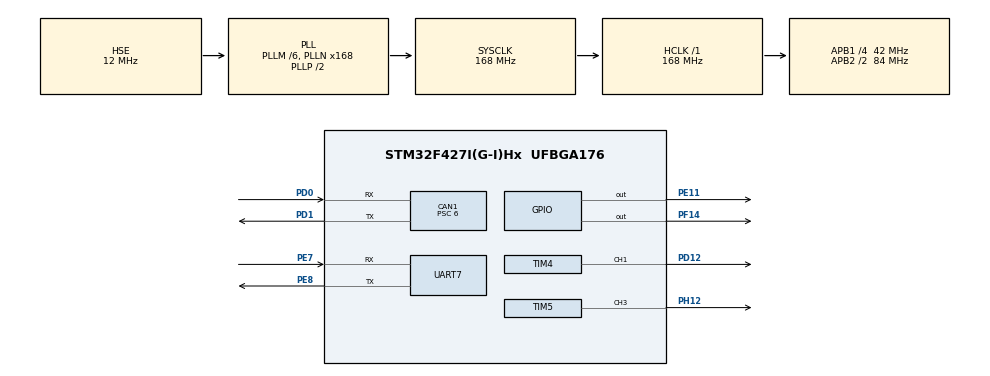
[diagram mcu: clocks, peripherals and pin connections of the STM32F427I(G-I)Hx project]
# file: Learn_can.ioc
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CAN1.AutoBusOff=DISABLE
CAN1.AutoRetransmission=DISABLE
CAN1.AutoWakeUp=DISABLE
CAN1.BS1=CAN_BS1_4TQ
CAN1.BS2=CAN_BS2_2TQ
CAN1.CalculateBaudRate=1000000
CAN1.CalculateTimeBit=1000
CAN1.CalculateTimeQuantum=142.85714285714286
CAN1.Mode=CAN_MODE_NORMAL
CAN1.Prescaler=6
CAN1.ReceiveFifoLocked=DISABLE
CAN1.SyncJumpWidth=CAN_SJW_1TQ
CAN1.TimeSeg1=CAN_BS1_4TQ
CAN1.TimeSeg2=CAN_BS2_2TQ
CAN1.TimeTriggeredMode=DISABLE
CAN1.TransmitFifoPriority=DISABLE
Mcu.Family=STM32F4
Mcu.Name=STM32F427I(G-I)Hx
Mcu.Package=UFBGA176
NVIC.CAN1_RX0_IRQn=true\:0\:0\:false\:false\:true\:true\:true\:true
NVIC.PriorityGroup=NVIC_PRIORITYGROUP_4
NVIC.UART7_IRQn=true\:1\:0\:false\:false\:true\:true\:true\:true
PA13.Mode=Serial_Wire
PA13.Signal=SYS_JTMS-SWDIO
PA14.Mode=Serial_Wire
PA14.Signal=SYS_JTCK-SWCLK
PC14/OSC32_IN.Mode=LSE-External-Oscillator
PC14/OSC32_IN.Signal=RCC_OSC32_IN
PC15/OSC32_OUT.Mode=LSE-External-Oscillator
PC15/OSC32_OUT.Signal=RCC_OSC32_OUT
PD0.Mode=CAN_Activate
PD0.Signal=CAN1_RX
PD1.Mode=CAN_Activate
PD1.Signal=CAN1_TX
PD12.Signal=S_TIM4_CH1
PE11.Signal=GPIO_Output
PE7.Mode=Asynchronous
PE7.Signal=UART7_RX
PE8.Mode=Asynchronous
PE8.Signal=UART7_TX
PF14.Signal=GPIO_Output
PH0/OSC_IN.Mode=HSE-External-Oscillator
PH0/OSC_IN.Signal=RCC_OSC_IN
PH1/OSC_OUT.Mode=HSE-External-Oscillator
PH1/OSC_OUT.Signal=RCC_OSC_OUT
PH12.Signal=S_TIM5_CH3
ProjectManager.HeapSize=0x200
ProjectManager.StackSize=0x400
ProjectManager.TargetToolchain=MDK-ARM V5.32
RCC.48MHZClocksFreq_Value=84000000
RCC.AHBFreq_Value=168000000
RCC.APB1CLKDivider=RCC_HCLK_DIV4
RCC.APB1Freq_Value=42000000
RCC.APB1TimFreq_Value=84000000
RCC.APB2CLKDivider=RCC_HCLK_DIV2
RCC.APB2Freq_Value=84000000
RCC.APB2TimFreq_Value=168000000
RCC.CortexFreq_Value=168000000
RCC.HCLKFreq_Value=168000000
RCC.HSE_VALUE=12000000
RCC.HSI_VALUE=16000000
RCC.PLLM=6
RCC.PLLN=168
RCC.PLLSourceVirtual=RCC_PLLSOURCE_HSE
RCC.SYSCLKFreq_VALUE=168000000
RCC.SYSCLKSource=RCC_SYSCLKSOURCE_PLLCLK
RCC.VCOOutputFreq_Value=336000000
SH.S_TIM4_CH1.0=TIM4_CH1,PWM Generation1 CH1
SH.S_TIM5_CH3.0=TIM5_CH3,PWM Generation3 CH3
TIM4.AutoReloadPreload=TIM_AUTORELOAD_PRELOAD_DISABLE
TIM4.Channel-PWM\ Generation1\ CH1=TIM_CHANNEL_1
TIM4.ClockDivision=TIM_CLOCKDIVISION_DIV1
TIM4.CounterMode=TIM_COUNTERMODE_UP
TIM4.Period=9999
TIM4.Prescaler=83
TIM5.AutoReloadPreload=TIM_AUTORELOAD_PRELOAD_DISABLE
TIM5.Channel-PWM\ Generation3\ CH3=TIM_CHANNEL_3
TIM5.ClockDivision=TIM_CLOCKDIVISION_DIV1
TIM5.CounterMode=TIM_COUNTERMODE_UP
TIM5.Period=9999
TIM5.Prescaler=83
UART7.VirtualMode=Asynchronous
board=custom

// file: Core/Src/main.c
/* USER CODE BEGIN Header */
/**
  ******************************************************************************
  * @file           : main.c
  * @brief          : Main program body
  ******************************************************************************
  * @attention
  *
  * Copyright (c) 2026 STMicroelectronics.
  * All rights reserved.
  *
  * This software is licensed under terms that can be found in the LICENSE file
  * in the root directory of this software component.
  * If no LICENSE file comes with this software, it is provided AS-IS.
  *
  ******************************************************************************
  */
/* USER CODE END Header */
#include "main.h"
#include "can.h"
#include "tim.h"
#include "usart.h"
#include "gpio.h"

/* USER CODE BEGIN Includes */
#include "base_app.h"
/* USER CODE END Includes */

void SystemClock_Config(void);

int main(void)
{

  /* MCU Configuration--------------------------------------------------------*/

  /* Reset of all peripherals, Initializes the Flash interface and the Systick. */
  HAL_Init();

  /* Configure the system clock */
  SystemClock_Config();

  /* Initialize all configured peripherals */
  /* 保留 CubeMX 生成的 GPIO、CAN、定时器和 UART 初始化。
   * TIM4/TIM5 在此只初始化外设；电机闭环不依赖它们的 PWM 输出，
   * 控制周期由 HAL_GetTick() 的 1 ms 系统节拍驱动。 */
  MX_GPIO_Init();
  MX_CAN1_Init();
  MX_TIM4_Init();
  MX_TIM5_Init();
  MX_UART7_Init();
  /* USER CODE BEGIN 2 */
  /* 配置 C620 CAN 接收过滤器、启动接收中断，并开启 UART7 单字节接收。 */
  base_app_init();

  /* USER CODE END 2 */

  /* Infinite loop */
  while (1)
  {

    /* USER CODE BEGIN 3 */
    /* 不阻塞主循环：解析排队命令、每毫秒更新电机状态机，
     * 并异步发送串口回复/调试数据。 */
    base_app_poll();
  }
  /* USER CODE END 3 */
}

void SystemClock_Config(void)
{
  RCC_OscInitTypeDef RCC_OscInitStruct = {0};
  RCC_ClkInitTypeDef RCC_ClkInitStruct = {0};

  /** Configure the main internal regulator output voltage
  */
  __HAL_RCC_PWR_CLK_ENABLE();
  __HAL_PWR_VOLTAGESCALING_CONFIG(PWR_REGULATOR_VOLTAGE_SCALE1);

  /** Initializes the RCC Oscillators according to the specified parameters
  * in the RCC_OscInitTypeDef structure.
  */
  RCC_OscInitStruct.OscillatorType = RCC_OSCILLATORTYPE_HSE;
  RCC_OscInitStruct.HSEState = RCC_HSE_ON;
  RCC_OscInitStruct.PLL.PLLState = RCC_PLL_ON;
  RCC_OscInitStruct.PLL.PLLSource = RCC_PLLSOURCE_HSE;
  RCC_OscInitStruct.PLL.PLLM = 6;
  RCC_OscInitStruct.PLL.PLLN = 168;
  RCC_OscInitStruct.PLL.PLLP = RCC_PLLP_DIV2;
  RCC_OscInitStruct.PLL.PLLQ = 4;
  if (HAL_RCC_OscConfig(&RCC_OscInitStruct) != HAL_OK)
  {
    Error_Handler();
  }

  /** Initializes the CPU, AHB and APB buses clocks
  */
  RCC_ClkInitStruct.ClockType = RCC_CLOCKTYPE_HCLK|RCC_CLOCKTYPE_SYSCLK
                              |RCC_CLOCKTYPE_PCLK1|RCC_CLOCKTYPE_PCLK2;
  RCC_ClkInitStruct.SYSCLKSource = RCC_SYSCLKSOURCE_PLLCLK;
  RCC_ClkInitStruct.AHBCLKDivider = RCC_SYSCLK_DIV1;
  RCC_ClkInitStruct.APB1CLKDivider = RCC_HCLK_DIV4;
  RCC_ClkInitStruct.APB2CLKDivider = RCC_HCLK_DIV2;

  if (HAL_RCC_ClockConfig(&RCC_ClkInitStruct, FLASH_LATENCY_5) != HAL_OK)
  {
    Error_Handler();
  }
}

/* USER CODE BEGIN 4 */
/* Callbacks are in base_app.c. */
/* USER CODE END 4 */

void Error_Handler(void)
{
  __disable_irq();
  while (1)
  {
  }
}
